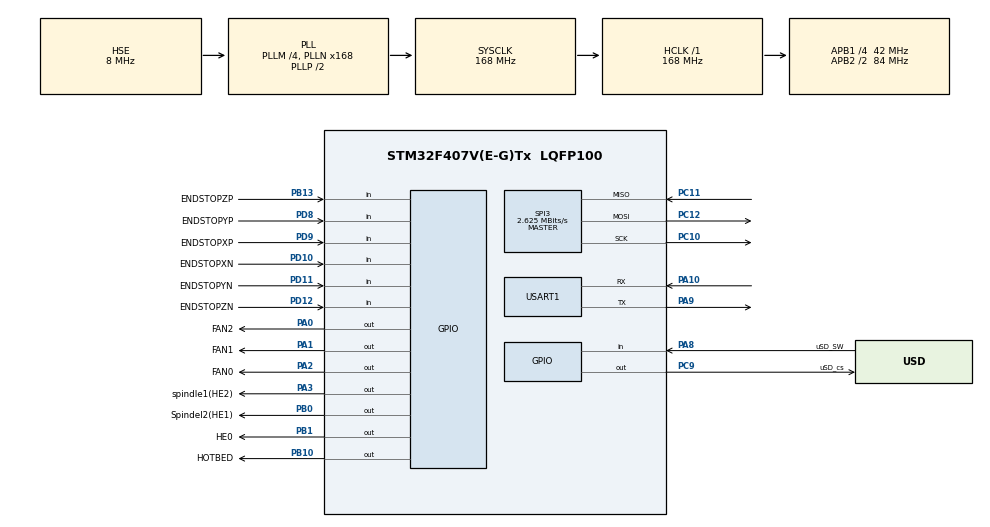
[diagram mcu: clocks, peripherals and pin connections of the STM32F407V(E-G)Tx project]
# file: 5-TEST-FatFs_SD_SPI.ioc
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FATFS._MAX_LFN=100
FATFS._USE_LFN=1
Mcu.Family=STM32F4
Mcu.Name=STM32F407V(E-G)Tx
Mcu.Package=LQFP100
NVIC.PriorityGroup=NVIC_PRIORITYGROUP_4
PA0-WKUP.GPIO_Label=FAN2
PA0-WKUP.Signal=GPIO_Output
PA1.GPIO_Label=FAN1
PA1.Signal=GPIO_Output
PA10.Mode=Asynchronous
PA10.Signal=USART1_RX
PA13.Mode=Serial_Wire
PA13.Signal=SYS_JTMS-SWDIO
PA14.Mode=Serial_Wire
PA14.Signal=SYS_JTCK-SWCLK
PA2.GPIO_Label=FAN0
PA2.Signal=GPIO_Output
PA3.GPIO_Label=spindle1(HE2)
PA3.Signal=GPIO_Output
PA8.GPIO_Label=uSD_SW
PA8.GPIO_PuPd=GPIO_PULLUP
PA8.Signal=GPIO_Input
PA9.Mode=Asynchronous
PA9.Signal=USART1_TX
PB0.GPIO_Label=Spindel2(HE1)
PB0.Signal=GPIO_Output
PB1.GPIO_Label=HE0
PB1.Signal=GPIO_Output
PB10.GPIO_Label=HOTBED
PB10.Signal=GPIO_Output
PB13.GPIO_Label=ENDSTOPZP
PB13.Signal=GPIO_Input
PC10.Mode=Full_Duplex_Master
PC10.Signal=SPI3_SCK
PC11.Mode=Full_Duplex_Master
PC11.Signal=SPI3_MISO
PC12.Mode=Full_Duplex_Master
PC12.Signal=SPI3_MOSI
PC9.GPIO_Label=uSD_cs
PC9.GPIO_PuPd=GPIO_PULLUP
PC9.PinState=GPIO_PIN_SET
PC9.Signal=GPIO_Output
PD10.GPIO_Label=ENDSTOPXN
PD10.Signal=GPIO_Input
PD11.GPIO_Label=ENDSTOPYN
PD11.Signal=GPIO_Input
PD12.GPIO_Label=ENDSTOPZN
PD12.Signal=GPIO_Input
PD8.GPIO_Label=ENDSTOPYP
PD8.Signal=GPIO_Input
PD9.GPIO_Label=ENDSTOPXP
PD9.Signal=GPIO_Input
PH0-OSC_IN.Mode=HSE-External-Oscillator
PH0-OSC_IN.Signal=RCC_OSC_IN
PH1-OSC_OUT.Mode=HSE-External-Oscillator
PH1-OSC_OUT.Signal=RCC_OSC_OUT
ProjectManager.HeapSize=0x800
ProjectManager.StackSize=0x800
ProjectManager.TargetToolchain=MDK-ARM V5.32
RCC.48MHZClocksFreq_Value=84000000
RCC.AHBFreq_Value=168000000
RCC.APB1CLKDivider=RCC_HCLK_DIV4
RCC.APB1Freq_Value=42000000
RCC.APB1TimFreq_Value=84000000
RCC.APB2CLKDivider=RCC_HCLK_DIV2
RCC.APB2Freq_Value=84000000
RCC.APB2TimFreq_Value=168000000
RCC.CortexFreq_Value=168000000
RCC.HCLKFreq_Value=168000000
RCC.HSE_VALUE=8000000
RCC.HSI_VALUE=16000000
RCC.LSE_VALUE=32768
RCC.PLLM=4
RCC.PLLN=168
RCC.PLLSourceVirtual=RCC_PLLSOURCE_HSE
RCC.SYSCLKFreq_VALUE=168000000
RCC.SYSCLKSource=RCC_SYSCLKSOURCE_PLLCLK
RCC.VCOOutputFreq_Value=336000000
SPI3.BaudRatePrescaler=SPI_BAUDRATEPRESCALER_16
SPI3.CalculateBaudRate=2.625 MBits/s
SPI3.Direction=SPI_DIRECTION_2LINES
SPI3.Mode=SPI_MODE_MASTER
SPI3.VirtualType=VM_MASTER
USART1.VirtualMode=VM_ASYNC
VP_FATFS_VS_Generic.Mode=User_defined
board=custom

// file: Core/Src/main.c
/* USER CODE BEGIN Header */
/**
  ******************************************************************************
  * @file           : main.c
  * @brief          : Main program body
  ******************************************************************************
  * @attention
  *
  * Copyright (c) 2026 STMicroelectronics.
  * All rights reserved.
  *
  * This software is licensed under terms that can be found in the LICENSE file
  * in the root directory of this software component.
  * If no LICENSE file comes with this software, it is provided AS-IS.
  *
  ******************************************************************************
  */
/* USER CODE END Header */
#include "main.h"
#include "fatfs.h"

/* USER CODE BEGIN Includes */
#include "MYAPP.H"
/* USER CODE END Includes */

SPI_HandleTypeDef hspi3;

UART_HandleTypeDef huart1;

void SystemClock_Config(void);
static void MX_GPIO_Init(void);
static void MX_USART1_UART_Init(void);
static void MX_SPI3_Init(void);

int main(void)
{

  /* MCU Configuration--------------------------------------------------------*/

  /* Reset of all peripherals, Initializes the Flash interface and the Systick. */
  HAL_Init();

  /* Configure the system clock */
  SystemClock_Config();

  /* Initialize all configured peripherals */
  MX_GPIO_Init();
  MX_USART1_UART_Init();
  MX_SPI3_Init();
  MX_FATFS_Init();

  /* Infinite loop */
  /* USER CODE BEGIN WHILE */
  while (1)
  {
		MY_APP();
    /* USER CODE END WHILE */

  }
}

void SystemClock_Config(void)
{
  RCC_OscInitTypeDef RCC_OscInitStruct = {0};
  RCC_ClkInitTypeDef RCC_ClkInitStruct = {0};

  /** Configure the main internal regulator output voltage
  */
  __HAL_RCC_PWR_CLK_ENABLE();
  __HAL_PWR_VOLTAGESCALING_CONFIG(PWR_REGULATOR_VOLTAGE_SCALE1);

  /** Initializes the RCC Oscillators according to the specified parameters
  * in the RCC_OscInitTypeDef structure.
  */
  RCC_OscInitStruct.OscillatorType = RCC_OSCILLATORTYPE_HSE;
  RCC_OscInitStruct.HSEState = RCC_HSE_ON;
  RCC_OscInitStruct.PLL.PLLState = RCC_PLL_ON;
  RCC_OscInitStruct.PLL.PLLSource = RCC_PLLSOURCE_HSE;
  RCC_OscInitStruct.PLL.PLLM = 4;
  RCC_OscInitStruct.PLL.PLLN = 168;
  RCC_OscInitStruct.PLL.PLLP = RCC_PLLP_DIV2;
  RCC_OscInitStruct.PLL.PLLQ = 4;
  if (HAL_RCC_OscConfig(&RCC_OscInitStruct) != HAL_OK)
  {
    Error_Handler();
  }

  /** Initializes the CPU, AHB and APB buses clocks
  */
  RCC_ClkInitStruct.ClockType = RCC_CLOCKTYPE_HCLK|RCC_CLOCKTYPE_SYSCLK
                              |RCC_CLOCKTYPE_PCLK1|RCC_CLOCKTYPE_PCLK2;
  RCC_ClkInitStruct.SYSCLKSource = RCC_SYSCLKSOURCE_PLLCLK;
  RCC_ClkInitStruct.AHBCLKDivider = RCC_SYSCLK_DIV1;
  RCC_ClkInitStruct.APB1CLKDivider = RCC_HCLK_DIV4;
  RCC_ClkInitStruct.APB2CLKDivider = RCC_HCLK_DIV2;

  if (HAL_RCC_ClockConfig(&RCC_ClkInitStruct, FLASH_LATENCY_5) != HAL_OK)
  {
    Error_Handler();
  }
}

static void MX_SPI3_Init(void)
{

  /* SPI3 parameter configuration*/
  hspi3.Instance = SPI3;
  hspi3.Init.Mode = SPI_MODE_MASTER;
  hspi3.Init.Direction = SPI_DIRECTION_2LINES;
  hspi3.Init.DataSize = SPI_DATASIZE_8BIT;
  hspi3.Init.CLKPolarity = SPI_POLARITY_LOW;
  hspi3.Init.CLKPhase = SPI_PHASE_1EDGE;
  hspi3.Init.NSS = SPI_NSS_SOFT;
  hspi3.Init.BaudRatePrescaler = SPI_BAUDRATEPRESCALER_16;
  hspi3.Init.FirstBit = SPI_FIRSTBIT_MSB;
  hspi3.Init.TIMode = SPI_TIMODE_DISABLE;
  hspi3.Init.CRCCalculation = SPI_CRCCALCULATION_DISABLE;
  hspi3.Init.CRCPolynomial = 10;
  if (HAL_SPI_Init(&hspi3) != HAL_OK)
  {
    Error_Handler();
  }

}

static void MX_USART1_UART_Init(void)
{

  huart1.Instance = USART1;
  huart1.Init.BaudRate = 115200;
  huart1.Init.WordLength = UART_WORDLENGTH_8B;
  huart1.Init.StopBits = UART_STOPBITS_1;
  huart1.Init.Parity = UART_PARITY_NONE;
  huart1.Init.Mode = UART_MODE_TX_RX;
  huart1.Init.HwFlowCtl = UART_HWCONTROL_NONE;
  huart1.Init.OverSampling = UART_OVERSAMPLING_16;
  if (HAL_UART_Init(&huart1) != HAL_OK)
  {
    Error_Handler();
  }

}

static void MX_GPIO_Init(void)
{
  GPIO_InitTypeDef GPIO_InitStruct = {0};

  /* GPIO Ports Clock Enable */
  __HAL_RCC_GPIOH_CLK_ENABLE();
  __HAL_RCC_GPIOA_CLK_ENABLE();
  __HAL_RCC_GPIOB_CLK_ENABLE();
  __HAL_RCC_GPIOD_CLK_ENABLE();
  __HAL_RCC_GPIOC_CLK_ENABLE();

  /*Configure GPIO pin Output Level */
  HAL_GPIO_WritePin(GPIOA, FAN2_Pin|FAN1_Pin|FAN0_Pin|spindle1_Pin, GPIO_PIN_RESET);

  /*Configure GPIO pin Output Level */
  HAL_GPIO_WritePin(GPIOB, Spindel2_Pin|HE0_Pin|HOTBED_Pin, GPIO_PIN_RESET);

  /*Configure GPIO pin Output Level */
  HAL_GPIO_WritePin(uSD_cs_GPIO_Port, uSD_cs_Pin, GPIO_PIN_SET);

  /*Configure GPIO pins : FAN2_Pin FAN1_Pin FAN0_Pin spindle1_Pin */
  GPIO_InitStruct.Pin = FAN2_Pin|FAN1_Pin|FAN0_Pin|spindle1_Pin;
  GPIO_InitStruct.Mode = GPIO_MODE_OUTPUT_PP;
  GPIO_InitStruct.Pull = GPIO_NOPULL;
  GPIO_InitStruct.Speed = GPIO_SPEED_FREQ_LOW;
  HAL_GPIO_Init(GPIOA, &GPIO_InitStruct);

  /*Configure GPIO pins : Spindel2_Pin HE0_Pin HOTBED_Pin */
  GPIO_InitStruct.Pin = Spindel2_Pin|HE0_Pin|HOTBED_Pin;
  GPIO_InitStruct.Mode = GPIO_MODE_OUTPUT_PP;
  GPIO_InitStruct.Pull = GPIO_NOPULL;
  GPIO_InitStruct.Speed = GPIO_SPEED_FREQ_LOW;
  HAL_GPIO_Init(GPIOB, &GPIO_InitStruct);

  /*Configure GPIO pin : ENDSTOPZP_Pin */
  GPIO_InitStruct.Pin = ENDSTOPZP_Pin;
  GPIO_InitStruct.Mode = GPIO_MODE_INPUT;
  GPIO_InitStruct.Pull = GPIO_NOPULL;
  HAL_GPIO_Init(ENDSTOPZP_GPIO_Port, &GPIO_InitStruct);

  /*Configure GPIO pins : ENDSTOPYP_Pin ENDSTOPXP_Pin ENDSTOPXN_Pin ENDSTOPYN_Pin
                           ENDSTOPZN_Pin */
  GPIO_InitStruct.Pin = ENDSTOPYP_Pin|ENDSTOPXP_Pin|ENDSTOPXN_Pin|ENDSTOPYN_Pin
                          |ENDSTOPZN_Pin;
  GPIO_InitStruct.Mode = GPIO_MODE_INPUT;
  GPIO_InitStruct.Pull = GPIO_NOPULL;
  HAL_GPIO_Init(GPIOD, &GPIO_InitStruct);

  /*Configure GPIO pin : uSD_cs_Pin */
  GPIO_InitStruct.Pin = uSD_cs_Pin;
  GPIO_InitStruct.Mode = GPIO_MODE_OUTPUT_PP;
  GPIO_InitStruct.Pull = GPIO_PULLUP;
  GPIO_InitStruct.Speed = GPIO_SPEED_FREQ_LOW;
  HAL_GPIO_Init(uSD_cs_GPIO_Port, &GPIO_InitStruct);

  /*Configure GPIO pin : uSD_SW_Pin */
  GPIO_InitStruct.Pin = uSD_SW_Pin;
  GPIO_InitStruct.Mode = GPIO_MODE_INPUT;
  GPIO_InitStruct.Pull = GPIO_PULLUP;
  HAL_GPIO_Init(uSD_SW_GPIO_Port, &GPIO_InitStruct);

}

void Error_Handler(void)
{
  __disable_irq();
  while (1)
  {
  }
}
